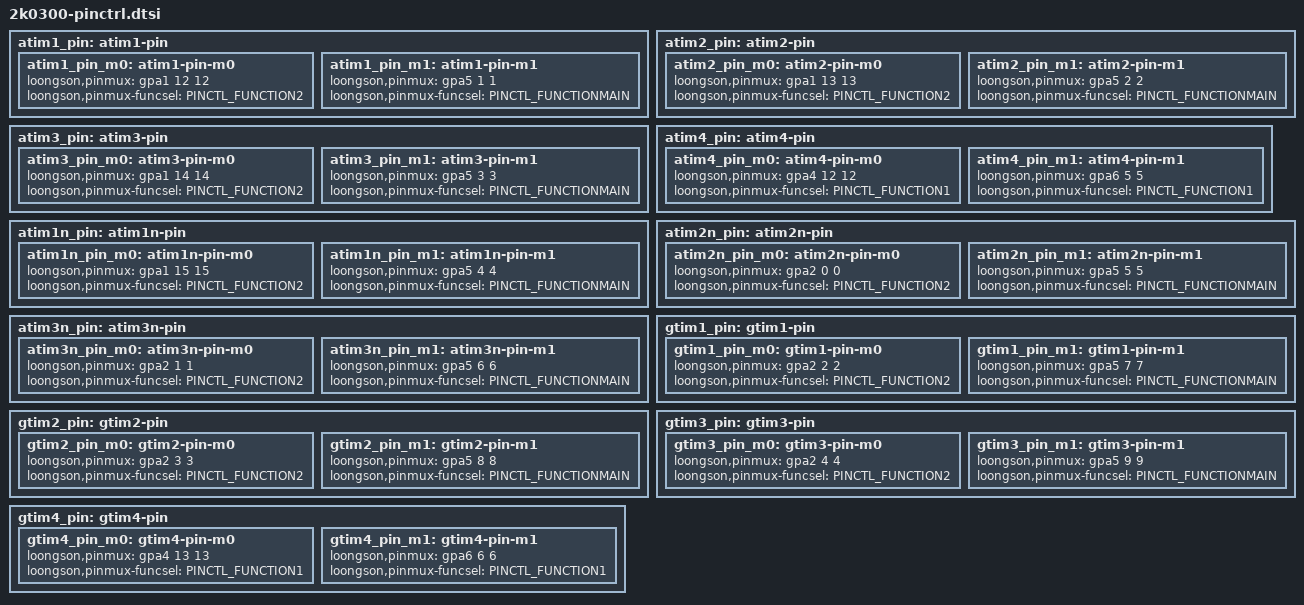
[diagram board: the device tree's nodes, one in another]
	atim1_pin: atim1-pin{
		atim1_pin_m0: atim1-pin-m0{
			loongson,pinmux = <&gpa1 12 12>;
			loongson,pinmux-funcsel = <PINCTL_FUNCTION2>;
		};
		atim1_pin_m1: atim1-pin-m1{
			loongson,pinmux = <&gpa5 1 1>;
			loongson,pinmux-funcsel = <PINCTL_FUNCTIONMAIN>;
		};
	};

	atim2_pin: atim2-pin{
		atim2_pin_m0: atim2-pin-m0{
			loongson,pinmux = <&gpa1 13 13>;
			loongson,pinmux-funcsel = <PINCTL_FUNCTION2>;
		};
		atim2_pin_m1: atim2-pin-m1{
			loongson,pinmux = <&gpa5 2 2>;
			loongson,pinmux-funcsel = <PINCTL_FUNCTIONMAIN>;
		};
	};

	atim3_pin: atim3-pin{
		atim3_pin_m0: atim3-pin-m0{
			loongson,pinmux = <&gpa1 14 14>;
			loongson,pinmux-funcsel = <PINCTL_FUNCTION2>;
		};
		atim3_pin_m1: atim3-pin-m1{
			loongson,pinmux = <&gpa5 3 3>;
			loongson,pinmux-funcsel = <PINCTL_FUNCTIONMAIN>;
		};
	};

	atim4_pin: atim4-pin{
		atim4_pin_m0: atim4-pin-m0{
			loongson,pinmux = <&gpa4 12 12>;
			loongson,pinmux-funcsel = <PINCTL_FUNCTION1>;
		};
		atim4_pin_m1: atim4-pin-m1{
			loongson,pinmux = <&gpa6 5 5>;
			loongson,pinmux-funcsel = <PINCTL_FUNCTION1>;
		};
	};

	atim1n_pin: atim1n-pin{
		atim1n_pin_m0: atim1n-pin-m0{
			loongson,pinmux = <&gpa1 15 15>;
			loongson,pinmux-funcsel = <PINCTL_FUNCTION2>;
		};
		atim1n_pin_m1: atim1n-pin-m1{
			loongson,pinmux = <&gpa5 4 4>;
			loongson,pinmux-funcsel = <PINCTL_FUNCTIONMAIN>;
		};
	};

	atim2n_pin: atim2n-pin{
		atim2n_pin_m0: atim2n-pin-m0{
			loongson,pinmux = <&gpa2 0 0>;
			loongson,pinmux-funcsel = <PINCTL_FUNCTION2>;
		};
		atim2n_pin_m1: atim2n-pin-m1{
			loongson,pinmux = <&gpa5 5 5>;
			loongson,pinmux-funcsel = <PINCTL_FUNCTIONMAIN>;
		};
	};

	atim3n_pin: atim3n-pin{
		atim3n_pin_m0: atim3n-pin-m0{
			loongson,pinmux = <&gpa2 1 1>;
			loongson,pinmux-funcsel = <PINCTL_FUNCTION2>;
		};
		atim3n_pin_m1: atim3n-pin-m1{
			loongson,pinmux = <&gpa5 6 6>;
			loongson,pinmux-funcsel = <PINCTL_FUNCTIONMAIN>;
		};
	};

	gtim1_pin: gtim1-pin{
		gtim1_pin_m0: gtim1-pin-m0{
			loongson,pinmux = <&gpa2 2 2>;
			loongson,pinmux-funcsel = <PINCTL_FUNCTION2>;
		};
		gtim1_pin_m1: gtim1-pin-m1{
			loongson,pinmux = <&gpa5 7 7>;
			loongson,pinmux-funcsel = <PINCTL_FUNCTIONMAIN>;
		};
	};

	gtim2_pin: gtim2-pin{
		gtim2_pin_m0: gtim2-pin-m0{
			loongson,pinmux = <&gpa2 3 3>;
			loongson,pinmux-funcsel = <PINCTL_FUNCTION2>;
		};
		gtim2_pin_m1: gtim2-pin-m1{
			loongson,pinmux = <&gpa5 8 8>;
			loongson,pinmux-funcsel = <PINCTL_FUNCTIONMAIN>;
		};
	};

	gtim3_pin: gtim3-pin{
		gtim3_pin_m0: gtim3-pin-m0{
			loongson,pinmux = <&gpa2 4 4>;
			loongson,pinmux-funcsel = <PINCTL_FUNCTION2>;
		};
		gtim3_pin_m1: gtim3-pin-m1{
			loongson,pinmux = <&gpa5 9 9>;
			loongson,pinmux-funcsel = <PINCTL_FUNCTIONMAIN>;
		};
	};

	gtim4_pin: gtim4-pin{
		gtim4_pin_m0: gtim4-pin-m0{
			loongson,pinmux = <&gpa4 13 13>;
			loongson,pinmux-funcsel = <PINCTL_FUNCTION1>;
		};
		gtim4_pin_m1: gtim4-pin-m1{
			loongson,pinmux = <&gpa6 6 6>;
			loongson,pinmux-funcsel = <PINCTL_FUNCTION1>;
		};
	};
